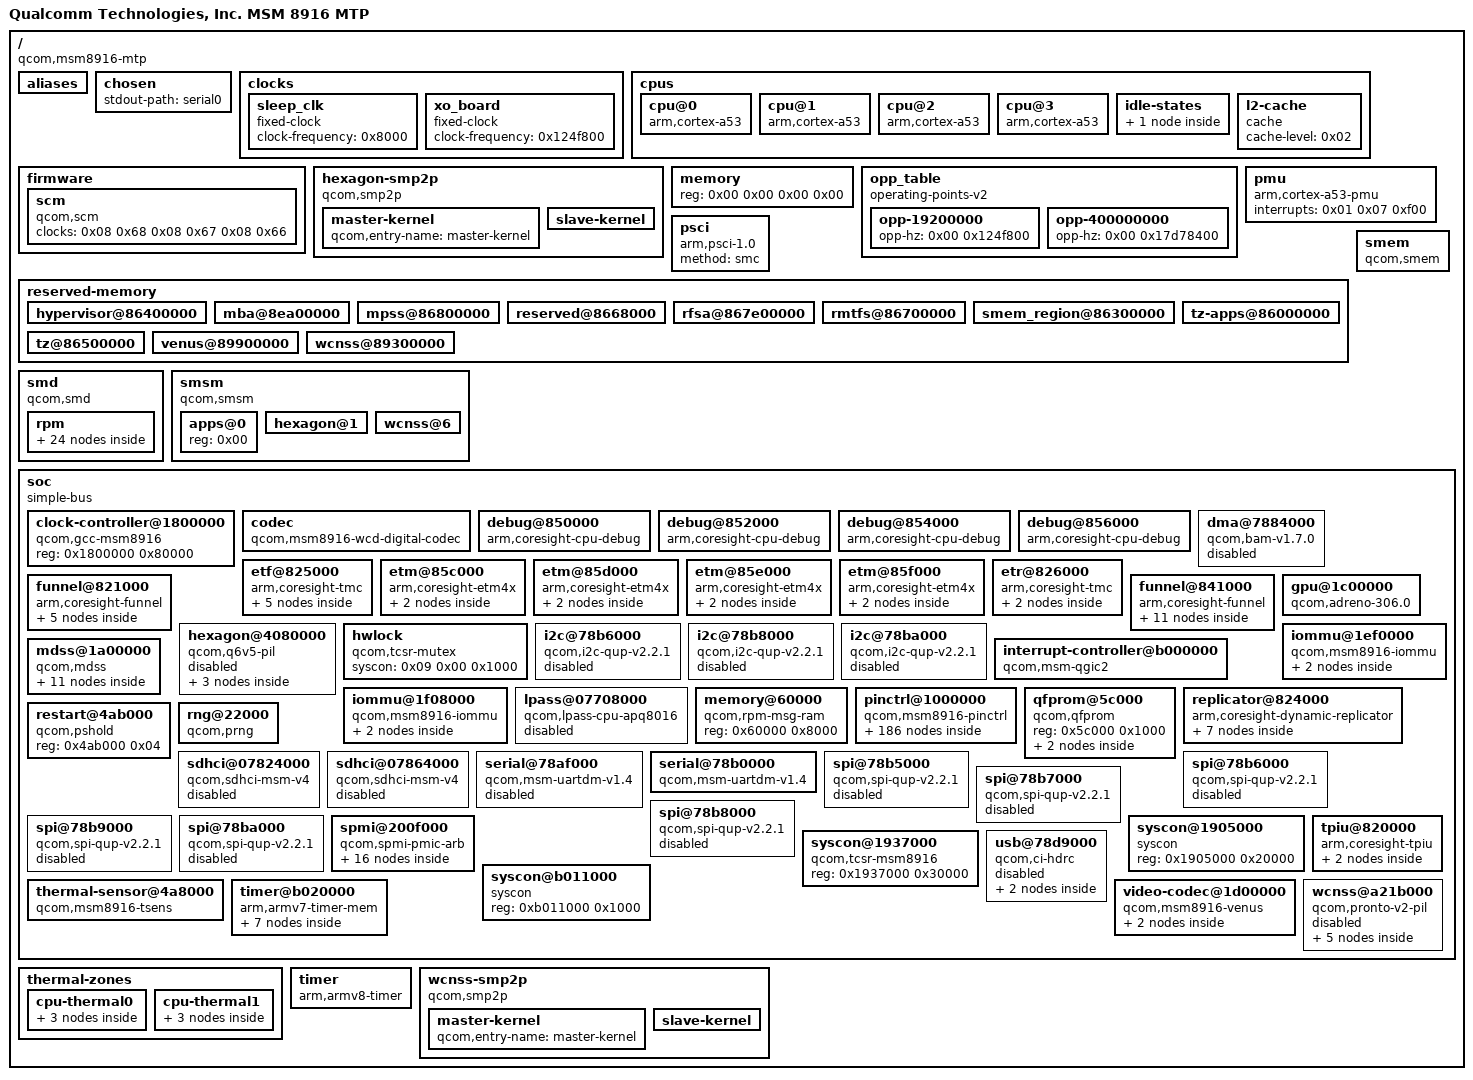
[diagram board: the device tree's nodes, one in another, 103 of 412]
/dts-v1/;

/ {
	#address-cells = <0x02>;
	#size-cells = <0x02>;
	compatible = "qcom,msm8916-mtp\0qcom,msm8916-mtp/1\0qcom,msm8916\0qcom,mtp";
	interrupt-parent = <0x01>;
	model = "Qualcomm Technologies, Inc. MSM 8916 MTP";

	__symbols__ {
		CPU0 = "/cpus/cpu@0";
		CPU1 = "/cpus/cpu@1";
		CPU2 = "/cpus/cpu@2";
		CPU3 = "/cpus/cpu@3";
		CPU_SPC = "/cpus/idle-states/spc";
		L2_0 = "/cpus/l2-cache";
		apcs = "/soc/syscon@b011000";
		apps_iommu = "/soc/iommu@1ef0000";
		apps_smsm = "/smsm/apps@0";
		blsp1_uart1 = "/soc/serial@78af000";
		blsp1_uart1_default = "/soc/pinctrl@1000000/blsp1_uart1_default";
		blsp1_uart1_sleep = "/soc/pinctrl@1000000/blsp1_uart1_sleep";
		blsp1_uart2 = "/soc/serial@78b0000";
		blsp1_uart2_default = "/soc/pinctrl@1000000/blsp1_uart2_default";
		blsp1_uart2_sleep = "/soc/pinctrl@1000000/blsp1_uart2_sleep";
		blsp_dma = "/soc/dma@7884000";
		blsp_i2c2 = "/soc/i2c@78b6000";
		blsp_i2c4 = "/soc/i2c@78b8000";
		blsp_i2c6 = "/soc/i2c@78ba000";
		blsp_spi1 = "/soc/spi@78b5000";
		blsp_spi2 = "/soc/spi@78b6000";
		blsp_spi3 = "/soc/spi@78b7000";
		blsp_spi4 = "/soc/spi@78b8000";
		blsp_spi5 = "/soc/spi@78b9000";
		blsp_spi6 = "/soc/spi@78ba000";
		cdc_dmic_lines_act = "/soc/pinctrl@1000000/cdc-dmic-lines/dmic_lines_on";
		cdc_dmic_lines_sus = "/soc/pinctrl@1000000/cdc-dmic-lines/dmic_lines_off";
		cdc_pdm_lines_act = "/soc/pinctrl@1000000/cdc-pdm-lines/pdm_lines_on";
		cdc_pdm_lines_sus = "/soc/pinctrl@1000000/cdc-pdm-lines/pdm_lines_off";
		cpu_alert0 = "/thermal-zones/cpu-thermal0/trips/trip0";
		cpu_alert1 = "/thermal-zones/cpu-thermal1/trips/trip0";
		cpu_crit0 = "/thermal-zones/cpu-thermal0/trips/trip1";
		cpu_crit1 = "/thermal-zones/cpu-thermal1/trips/trip1";
		cross_conn_det_act = "/soc/pinctrl@1000000/cross-conn-det/lines_on";
		cross_conn_det_sus = "/soc/pinctrl@1000000/cross-conn-det/lines_off";
		dsi0 = "/soc/mdss@1a00000/dsi@1a98000";
		dsi0_in = "/soc/mdss@1a00000/dsi@1a98000/ports/port@0/endpoint";
		dsi0_out = "/soc/mdss@1a00000/dsi@1a98000/ports/port@1/endpoint";
		dsi_phy0 = "/soc/mdss@1a00000/dsi-phy@1a98300";
		etf_in = "/soc/etf@825000/ports/port@0/endpoint";
		etf_out = "/soc/etf@825000/ports/port@1/endpoint";
		etm0_out = "/soc/etm@85c000/port/endpoint";
		etm1_out = "/soc/etm@85d000/port/endpoint";
		etm2_out = "/soc/etm@85e000/port/endpoint";
		etm3_out = "/soc/etm@85f000/port/endpoint";
		etr_in = "/soc/etr@826000/port/endpoint";
		ext_codec_lines_act = "/soc/pinctrl@1000000/ext-codec-lines/lines_on";
		ext_codec_lines_sus = "/soc/pinctrl@1000000/ext-codec-lines/lines_off";
		ext_mclk_tlmm_lines_act = "/soc/pinctrl@1000000/ext-mclk-tlmm-lines/mclk_lines_on";
		ext_mclk_tlmm_lines_sus = "/soc/pinctrl@1000000/ext-mclk-tlmm-lines/mclk_lines_off";
		ext_pri_tlmm_lines_act = "/soc/pinctrl@1000000/ext-pri-tlmm-lines/ext_pa_on";
		ext_pri_tlmm_lines_sus = "/soc/pinctrl@1000000/ext-pri-tlmm-lines/ext_pa_off";
		ext_pri_ws_act = "/soc/pinctrl@1000000/ext-pri-ws-line/ext_pa_on";
		ext_pri_ws_sus = "/soc/pinctrl@1000000/ext-pri-ws-line/ext_pa_off";
		ext_sec_tlmm_lines_act = "/soc/pinctrl@1000000/ext-sec-tlmm-lines/tlmm_lines_on";
		ext_sec_tlmm_lines_sus = "/soc/pinctrl@1000000/ext-sec-tlmm-lines/tlmm_lines_off";
		funnel0_in4 = "/soc/funnel@821000/ports/port@4/endpoint";
		funnel0_out = "/soc/funnel@821000/ports/port@8/endpoint";
		funnel1_in0 = "/soc/funnel@841000/ports/port@0/endpoint";
		funnel1_in1 = "/soc/funnel@841000/ports/port@1/endpoint";
		funnel1_in2 = "/soc/funnel@841000/ports/port@2/endpoint";
		funnel1_in3 = "/soc/funnel@841000/ports/port@3/endpoint";
		funnel1_out = "/soc/funnel@841000/ports/port@4/endpoint";
		gcc = "/soc/clock-controller@1800000";
		gpu_iommu = "/soc/iommu@1f08000";
		gpu_opp_table = "/opp_table";
		hexagon_smp2p_in = "/hexagon-smp2p/slave-kernel";
		hexagon_smp2p_out = "/hexagon-smp2p/master-kernel";
		hexagon_smsm = "/smsm/hexagon@1";
		i2c2_default = "/soc/pinctrl@1000000/i2c2_default";
		i2c2_sleep = "/soc/pinctrl@1000000/i2c2_sleep";
		i2c4_default = "/soc/pinctrl@1000000/i2c4_default";
		i2c4_sleep = "/soc/pinctrl@1000000/i2c4_sleep";
		i2c6_default = "/soc/pinctrl@1000000/i2c6_default";
		i2c6_sleep = "/soc/pinctrl@1000000/i2c6_sleep";
		intc = "/soc/interrupt-controller@b000000";
		lpass = "/soc/lpass@07708000";
		lpass_codec = "/soc/codec";
		mba_mem = "/reserved-memory/mba@8ea00000";
		mdp = "/soc/mdss@1a00000/mdp@1a01000";
		mdp5_intf1_out = "/soc/mdss@1a00000/mdp@1a01000/ports/port@0/endpoint";
		mdss = "/soc/mdss@1a00000";
		mpss_mem = "/reserved-memory/mpss@86800000";
		msmgpio = "/soc/pinctrl@1000000";
		otg = "/soc/usb@78d9000";
		pm8916_0 = "/soc/spmi@200f000/pm8916@0";
		pm8916_1 = "/soc/spmi@200f000/pm8916@1";
		pm8916_gpios = "/soc/spmi@200f000/pm8916@0/gpios@c000";
		pm8916_l1 = "/smd/rpm/rpm_requests/pm8916-regulators/l1";
		pm8916_l10 = "/smd/rpm/rpm_requests/pm8916-regulators/l10";
		pm8916_l11 = "/smd/rpm/rpm_requests/pm8916-regulators/l11";
		pm8916_l12 = "/smd/rpm/rpm_requests/pm8916-regulators/l12";
		pm8916_l13 = "/smd/rpm/rpm_requests/pm8916-regulators/l13";
		pm8916_l14 = "/smd/rpm/rpm_requests/pm8916-regulators/l14";
		pm8916_l15 = "/smd/rpm/rpm_requests/pm8916-regulators/l15";
		pm8916_l16 = "/smd/rpm/rpm_requests/pm8916-regulators/l16";
		pm8916_l17 = "/smd/rpm/rpm_requests/pm8916-regulators/l17";
		pm8916_l18 = "/smd/rpm/rpm_requests/pm8916-regulators/l18";
		pm8916_l2 = "/smd/rpm/rpm_requests/pm8916-regulators/l2";
		pm8916_l3 = "/smd/rpm/rpm_requests/pm8916-regulators/l3";
		pm8916_l4 = "/smd/rpm/rpm_requests/pm8916-regulators/l4";
		pm8916_l5 = "/smd/rpm/rpm_requests/pm8916-regulators/l5";
		pm8916_l6 = "/smd/rpm/rpm_requests/pm8916-regulators/l6";
		pm8916_l7 = "/smd/rpm/rpm_requests/pm8916-regulators/l7";
		pm8916_l8 = "/smd/rpm/rpm_requests/pm8916-regulators/l8";
		pm8916_l9 = "/smd/rpm/rpm_requests/pm8916-regulators/l9";
		pm8916_mpps = "/soc/spmi@200f000/pm8916@0/mpps@a000";
		pm8916_s1 = "/smd/rpm/rpm_requests/pm8916-regulators/s1";
		pm8916_s3 = "/smd/rpm/rpm_requests/pm8916-regulators/s3";
		pm8916_s4 = "/smd/rpm/rpm_requests/pm8916-regulators/s4";
		pm8916_temp = "/soc/spmi@200f000/pm8916@0/temp-alarm@2400";
		pm8916_vadc = "/soc/spmi@200f000/pm8916@0/vadc@3100";
		pronto = "/soc/wcnss@a21b000";
		qfprom = "/soc/qfprom@5c000";
		replicator_in = "/soc/replicator@824000/ports/port@2/endpoint";
		replicator_out0 = "/soc/replicator@824000/ports/port@0/endpoint";
		replicator_out1 = "/soc/replicator@824000/ports/port@1/endpoint";
		rpm_msg_ram = "/soc/memory@60000";
		rpmcc = "/smd/rpm/rpm_requests/qcom,rpmcc";
		scm = "/firmware/scm";
		sdc1_clk_off = "/soc/pinctrl@1000000/pmx_sdc1_clk/clk_off";
		sdc1_clk_on = "/soc/pinctrl@1000000/pmx_sdc1_clk/clk_on";
		sdc1_cmd_off = "/soc/pinctrl@1000000/pmx_sdc1_cmd/cmd_off";
		sdc1_cmd_on = "/soc/pinctrl@1000000/pmx_sdc1_cmd/cmd_on";
		sdc1_data_off = "/soc/pinctrl@1000000/pmx_sdc1_data/data_off";
		sdc1_data_on = "/soc/pinctrl@1000000/pmx_sdc1_data/data_on";
		sdc2_cd_off = "/soc/pinctrl@1000000/sdhc2_cd_pin/cd_off";
		sdc2_cd_on = "/soc/pinctrl@1000000/sdhc2_cd_pin/cd_on";
		sdc2_clk_off = "/soc/pinctrl@1000000/pmx_sdc2_clk/clk_off";
		sdc2_clk_on = "/soc/pinctrl@1000000/pmx_sdc2_clk/clk_on";
		sdc2_cmd_off = "/soc/pinctrl@1000000/pmx_sdc2_cmd/cmd_off";
		sdc2_cmd_on = "/soc/pinctrl@1000000/pmx_sdc2_cmd/cmd_on";
		sdc2_data_off = "/soc/pinctrl@1000000/pmx_sdc2_data/data_off";
		sdc2_data_on = "/soc/pinctrl@1000000/pmx_sdc2_data/data_on";
		sdhc_1 = "/soc/sdhci@07824000";
		sdhc_2 = "/soc/sdhci@07864000";
		sleep_clk = "/clocks/sleep_clk";
		smd_rpm_regulators = "/smd/rpm/rpm_requests/pm8916-regulators";
		smem_mem = "/reserved-memory/smem_region@86300000";
		soc = "/soc";
		spi1_default = "/soc/pinctrl@1000000/spi1_default";
		spi1_sleep = "/soc/pinctrl@1000000/spi1_sleep";
		spi2_default = "/soc/pinctrl@1000000/spi2_default";
		spi2_sleep = "/soc/pinctrl@1000000/spi2_sleep";
		spi3_default = "/soc/pinctrl@1000000/spi3_default";
		spi3_sleep = "/soc/pinctrl@1000000/spi3_sleep";
		spi4_default = "/soc/pinctrl@1000000/spi4_default";
		spi4_sleep = "/soc/pinctrl@1000000/spi4_sleep";
		spi5_default = "/soc/pinctrl@1000000/spi5_default";
		spi5_sleep = "/soc/pinctrl@1000000/spi5_sleep";
		spi6_default = "/soc/pinctrl@1000000/spi6_default";
		spi6_sleep = "/soc/pinctrl@1000000/spi6_sleep";
		spmi_bus = "/soc/spmi@200f000";
		tcsr = "/soc/syscon@1937000";
		tcsr_mutex = "/soc/hwlock";
		tcsr_mutex_regs = "/soc/syscon@1905000";
		tpiu_in = "/soc/tpiu@820000/port/endpoint";
		tsens = "/soc/thermal-sensor@4a8000";
		tsens_caldata = "/soc/qfprom@5c000/caldata@d0";
		tsens_calsel = "/soc/qfprom@5c000/calsel@ec";
		usb_hs_phy = "/soc/usb@78d9000/ulpi/phy";
		venus = "/soc/video-codec@1d00000";
		venus_mem = "/reserved-memory/venus@89900000";
		wcd_codec = "/soc/spmi@200f000/pm8916@1/codec@f000";
		wcnss_mem = "/reserved-memory/wcnss@89300000";
		wcnss_pin_a = "/soc/pinctrl@1000000/wcnss-active";
		wcnss_smp2p_in = "/wcnss-smp2p/slave-kernel";
		wcnss_smp2p_out = "/wcnss-smp2p/master-kernel";
		wcnss_smsm = "/smsm/wcnss@6";
		xo_board = "/clocks/xo_board";
	};

	aliases {
		sdhc1 = "/soc/sdhci@07824000";
		sdhc2 = "/soc/sdhci@07864000";
		serial0 = "/soc/serial@78b0000";
		usid0 = "/soc/spmi@200f000/pm8916@0";
	};

	chosen {
		stdout-path = "serial0";
	};

	clocks {

		sleep_clk {
			#clock-cells = <0x00>;
			clock-frequency = <0x8000>;
			compatible = "fixed-clock";
			phandle = <0x5d>;
		};

		xo_board {
			#clock-cells = <0x00>;
			clock-frequency = <0x124f800>;
			compatible = "fixed-clock";
			phandle = <0x1f>;
		};
	};

	cpus {
		#address-cells = <0x01>;
		#size-cells = <0x00>;

		cpu@0 {
			compatible = "arm,cortex-a53\0arm,armv8";
			cpu-idle-states = <0x03>;
			device_type = "cpu";
			enable-method = "psci";
			next-level-cache = <0x02>;
			phandle = <0x50>;
			reg = <0x00>;
		};

		cpu@1 {
			compatible = "arm,cortex-a53\0arm,armv8";
			cpu-idle-states = <0x03>;
			device_type = "cpu";
			enable-method = "psci";
			next-level-cache = <0x02>;
			phandle = <0x51>;
			reg = <0x01>;
		};

		cpu@2 {
			compatible = "arm,cortex-a53\0arm,armv8";
			cpu-idle-states = <0x03>;
			device_type = "cpu";
			enable-method = "psci";
			next-level-cache = <0x02>;
			phandle = <0x52>;
			reg = <0x02>;
		};

		cpu@3 {
			compatible = "arm,cortex-a53\0arm,armv8";
			cpu-idle-states = <0x03>;
			device_type = "cpu";
			enable-method = "psci";
			next-level-cache = <0x02>;
			phandle = <0x53>;
			reg = <0x03>;
		};

		idle-states {

			spc {
				arm,psci-suspend-param = <0x40000002>;
				compatible = "arm,idle-state";
				entry-latency-us = <0x82>;
				exit-latency-us = <0x96>;
				local-timer-stop;
				min-residency-us = <0x7d0>;
				phandle = <0x03>;
			};
		};

		l2-cache {
			cache-level = <0x02>;
			compatible = "cache";
			phandle = <0x02>;
		};
	};

	firmware {

		scm {
			#reset-cells = <0x01>;
			clock-names = "core\0bus\0iface";
			clocks = <0x08 0x68 0x08 0x67 0x08 0x66>;
			compatible = "qcom,scm";
			phandle = <0x31>;
		};
	};

	hexagon-smp2p {
		compatible = "qcom,smp2p";
		interrupts = <0x00 0x1b 0x01>;
		qcom,ipc = <0x38 0x08 0x0e>;
		qcom,local-pid = <0x00>;
		qcom,remote-pid = <0x01>;
		qcom,smem = <0x1b3 0x1ac>;

		master-kernel {
			#qcom,smem-state-cells = <0x01>;
			phandle = <0x30>;
			qcom,entry-name = "master-kernel";
		};

		slave-kernel {
			#interrupt-cells = <0x02>;
			interrupt-controller;
			phandle = <0x2f>;
			qcom,entry-name = "slave-kernel";
		};
	};

	memory {
		device_type = "memory";
		reg = <0x00 0x00 0x00 0x00>;
	};

	opp_table {
		compatible = "operating-points-v2";
		phandle = <0x28>;

		opp-19200000 {
			opp-hz = <0x00 0x124f800>;
		};

		opp-400000000 {
			opp-hz = <0x00 0x17d78400>;
		};
	};

	pmu {
		compatible = "arm,cortex-a53-pmu";
		interrupts = <0x01 0x07 0xf00>;
	};

	psci {
		compatible = "arm,psci-1.0";
		method = "smc";
	};

	reserved-memory {
		#address-cells = <0x02>;
		#size-cells = <0x02>;
		ranges;

		hypervisor@86400000 {
			no-map;
			reg = <0x00 0x86400000 0x00 0x100000>;
		};

		mba@8ea00000 {
			no-map;
			phandle = <0x36>;
			reg = <0x00 0x8ea00000 0x00 0x100000>;
		};

		mpss@86800000 {
			no-map;
			phandle = <0x37>;
			reg = <0x00 0x86800000 0x00 0x2b00000>;
		};

		reserved@8668000 {
			no-map;
			reg = <0x00 0x86680000 0x00 0x80000>;
		};

		rfsa@867e00000 {
			no-map;
			reg = <0x00 0x867e0000 0x00 0x20000>;
		};

		rmtfs@86700000 {
			no-map;
			reg = <0x00 0x86700000 0x00 0xe0000>;
		};

		smem_region@86300000 {
			no-map;
			phandle = <0x05>;
			reg = <0x00 0x86300000 0x00 0x100000>;
		};

		tz-apps@86000000 {
			no-map;
			reg = <0x00 0x86000000 0x00 0x300000>;
		};

		tz@86500000 {
			no-map;
			reg = <0x00 0x86500000 0x00 0x180000>;
		};

		venus@89900000 {
			no-map;
			phandle = <0x58>;
			reg = <0x00 0x89900000 0x00 0x600000>;
		};

		wcnss@89300000 {
			no-map;
			phandle = <0x39>;
			reg = <0x00 0x89300000 0x00 0x600000>;
		};
	};

	smd {
		compatible = "qcom,smd";

		rpm {
			interrupts = <0x00 0xa8 0x01>;
			qcom,ipc = <0x38 0x08 0x00>;
			qcom,smd-edge = <0x0f>;

			rpm_requests {
				compatible = "qcom,rpm-msm8916";
				qcom,smd-channels = "rpm_requests";

				pm8916-regulators {
					compatible = "qcom,rpm-pm8916-regulators";
					phandle = <0x9a>;

					l1 {
						phandle = <0x9c>;
					};

					l10 {
						phandle = <0xa1>;
					};

					l11 {
						phandle = <0xa2>;
					};

					l12 {
						phandle = <0xa3>;
					};

					l13 {
						phandle = <0x25>;
					};

					l14 {
						phandle = <0xa4>;
					};

					l15 {
						phandle = <0xa5>;
					};

					l16 {
						phandle = <0xa6>;
					};

					l17 {
						phandle = <0xa7>;
					};

					l18 {
						phandle = <0xa8>;
					};

					l2 {
						phandle = <0x9d>;
					};

					l3 {
						phandle = <0x33>;
					};

					l4 {
						phandle = <0x9e>;
					};

					l5 {
						phandle = <0x24>;
					};

					l6 {
						phandle = <0x9f>;
					};

					l7 {
						phandle = <0x34>;
					};

					l8 {
						phandle = <0xa0>;
					};

					l9 {
						phandle = <0x3f>;
					};

					s1 {
						phandle = <0x32>;
					};

					s3 {
						phandle = <0x3e>;
					};

					s4 {
						phandle = <0x9b>;
					};
				};

				qcom,rpmcc {
					#clock-cells = <0x01>;
					compatible = "qcom,rpmcc-msm8916";
					phandle = <0x3d>;
				};
			};
		};
	};

	smem {
		compatible = "qcom,smem";
		hwlocks = <0x07 0x03>;
		memory-region = <0x05>;
		qcom,rpm-msg-ram = <0x06>;
	};

	smsm {
		#address-cells = <0x01>;
		#size-cells = <0x00>;
		compatible = "qcom,smsm";
		qcom,ipc-1 = <0x38 0x08 0x0d>;
		qcom,ipc-3 = <0x38 0x08 0x13>;

		apps@0 {
			#qcom,smem-state-cells = <0x01>;
			phandle = <0x41>;
			reg = <0x00>;
		};

		hexagon@1 {
			#interrupt-cells = <0x02>;
			interrupt-controller;
			interrupts = <0x00 0x1a 0x01>;
			phandle = <0xa9>;
			reg = <0x01>;
		};

		wcnss@6 {
			#interrupt-cells = <0x02>;
			interrupt-controller;
			interrupts = <0x00 0x90 0x01>;
			phandle = <0xaa>;
			reg = <0x06>;
		};
	};

	soc {
		#address-cells = <0x01>;
		#size-cells = <0x01>;
		compatible = "simple-bus";
		phandle = <0x5e>;
		ranges = <0x00 0x00 0x00 0xffffffff>;

		clock-controller@1800000 {
			#clock-cells = <0x01>;
			#power-domain-cells = <0x01>;
			#reset-cells = <0x01>;
			compatible = "qcom,gcc-msm8916";
			phandle = <0x08>;
			reg = <0x1800000 0x80000>;
		};

		codec {
			#sound-dai-cells = <0x01>;
			clock-names = "ahbix-clk\0mclk";
			clocks = <0x08 0x9a 0x08 0x9f>;
			compatible = "qcom,msm8916-wcd-digital-codec";
			phandle = <0x8c>;
			reg = <0x771c000 0x400>;
		};

		debug@850000 {
			clock-names = "apb_pclk";
			clocks = <0x3d 0x08>;
			compatible = "arm,coresight-cpu-debug\0arm,primecell";
			cpu = <0x50>;
			reg = <0x850000 0x1000>;
		};

		debug@852000 {
			clock-names = "apb_pclk";
			clocks = <0x3d 0x08>;
			compatible = "arm,coresight-cpu-debug\0arm,primecell";
			cpu = <0x51>;
			reg = <0x852000 0x1000>;
		};

		debug@854000 {
			clock-names = "apb_pclk";
			clocks = <0x3d 0x08>;
			compatible = "arm,coresight-cpu-debug\0arm,primecell";
			cpu = <0x52>;
			reg = <0x854000 0x1000>;
		};

		debug@856000 {
			clock-names = "apb_pclk";
			clocks = <0x3d 0x08>;
			compatible = "arm,coresight-cpu-debug\0arm,primecell";
			cpu = <0x53>;
			reg = <0x856000 0x1000>;
		};

		dma@7884000 {
			#dma-cells = <0x01>;
			clock-names = "bam_clk";
			clocks = <0x08 0x36>;
			compatible = "qcom,bam-v1.7.0";
			interrupts = <0x00 0xee 0x04>;
			phandle = <0x0a>;
			qcom,ee = <0x00>;
			reg = <0x7884000 0x23000>;
			status = "disabled";
		};

		etf@825000 {
			clock-names = "apb_pclk\0atclk";
			clocks = <0x3d 0x08 0x3d 0x09>;
			compatible = "arm,coresight-tmc\0arm,primecell";
			reg = <0x825000 0x1000>;

			ports {
				#address-cells = <0x01>;
				#size-cells = <0x00>;

				port@0 {
					reg = <0x00>;

					endpoint {
						phandle = <0x44>;
						remote-endpoint = <0x48>;
						slave-mode;
					};
				};

				port@1 {
					reg = <0x00>;

					endpoint {
						phandle = <0x47>;
						remote-endpoint = <0x49>;
					};
				};
			};
		};

		etm@85c000 {
			clock-names = "apb_pclk\0atclk";
			clocks = <0x3d 0x08 0x3d 0x09>;
			compatible = "arm,coresight-etm4x\0arm,primecell";
			cpu = <0x50>;
			reg = <0x85c000 0x1000>;

			port {

				endpoint {
					phandle = <0x4b>;
					remote-endpoint = <0x54>;
				};
			};
		};

		etm@85d000 {
			clock-names = "apb_pclk\0atclk";
			clocks = <0x3d 0x08 0x3d 0x09>;
			compatible = "arm,coresight-etm4x\0arm,primecell";
			cpu = <0x51>;
			reg = <0x85d000 0x1000>;

			port {

				endpoint {
					phandle = <0x4c>;
					remote-endpoint = <0x55>;
				};
			};
		};

		etm@85e000 {
			clock-names = "apb_pclk\0atclk";
			clocks = <0x3d 0x08 0x3d 0x09>;
			compatible = "arm,coresight-etm4x\0arm,primecell";
			cpu = <0x52>;
			reg = <0x85e000 0x1000>;

			port {

				endpoint {
					phandle = <0x4d>;
					remote-endpoint = <0x56>;
				};
			};
		};

		etm@85f000 {
			clock-names = "apb_pclk\0atclk";
			clocks = <0x3d 0x08 0x3d 0x09>;
			compatible = "arm,coresight-etm4x\0arm,primecell";
			cpu = <0x53>;
			reg = <0x85f000 0x1000>;

			port {

				endpoint {
					phandle = <0x4e>;
					remote-endpoint = <0x57>;
				};
			};
		};

		etr@826000 {
			clock-names = "apb_pclk\0atclk";
			clocks = <0x3d 0x08 0x3d 0x09>;
			compatible = "arm,coresight-tmc\0arm,primecell";
			reg = <0x826000 0x1000>;

			port {

				endpoint {
					phandle = <0x45>;
					remote-endpoint = <0x4a>;
					slave-mode;
				};
			};
		};

		funnel@821000 {
			clock-names = "apb_pclk\0atclk";
			clocks = <0x3d 0x08 0x3d 0x09>;
			compatible = "arm,coresight-funnel\0arm,primecell";
			reg = <0x821000 0x1000>;

			ports {
				#address-cells = <0x01>;
				#size-cells = <0x00>;

				port@4 {
					reg = <0x04>;

					endpoint {
						phandle = <0x4f>;
						remote-endpoint = <0x43>;
						slave-mode;
					};
				};

				port@8 {
					reg = <0x00>;

					endpoint {
						phandle = <0x48>;
						remote-endpoint = <0x44>;
					};
				};
			};
		};

		funnel@841000 {
			clock-names = "apb_pclk\0atclk";
			clocks = <0x3d 0x08 0x3d 0x09>;
			compatible = "arm,coresight-funnel\0arm,primecell";
			reg = <0x841000 0x1000>;

			ports {
				#address-cells = <0x01>;
				#size-cells = <0x00>;

				port@0 {
					reg = <0x00>;

					endpoint {
						phandle = <0x54>;
						remote-endpoint = <0x4b>;
						slave-mode;
					};
				};

				port@1 {
					reg = <0x01>;

					endpoint {
						phandle = <0x55>;
						remote-endpoint = <0x4c>;
						slave-mode;
					};
				};

				port@2 {
					reg = <0x02>;

					endpoint {
						phandle = <0x56>;
						remote-endpoint = <0x4d>;
						slave-mode;
					};
				};

				port@3 {
					reg = <0x03>;

					endpoint {
						phandle = <0x57>;
						remote-endpoint = <0x4e>;
						slave-mode;
					};
				};

				port@4 {
					reg = <0x00>;

					endpoint {
						phandle = <0x43>;
						remote-endpoint = <0x4f>;
					};
				};
			};
		};

		gpu@1c00000 {
			clock-names = "core\0iface\0mem\0mem_iface\0alt_mem_iface\0gfx3d";
			clocks = <0x08 0x76 0x08 0x75 0x08 0x69 0x08 0x8e 0x08 0x8f 0x08 0x0e>;
			compatible = "qcom,adreno-306.0\0qcom,adreno";
			interrupt-names = "kgsl_3d0_irq";
			interrupts = <0x00 0x21 0x04>;
			iommus = <0x29 0x01 0x29 0x02>;
			operating-points-v2 = <0x28>;
			power-domains = <0x08 0x05>;
			reg = <0x1c00000 0x20000>;
			reg-names = "kgsl_3d0_reg_memory";
		};

		hexagon@4080000 {
			clock-names = "iface\0bus\0mem\0xo";
			clocks = <0x08 0x74 0x08 0xa0 0x08 0x46 0x1f>;
			compatible = "qcom,q6v5-pil";
			cx-supply = <0x32>;
			interrupt-names = "wdog\0fatal\0ready\0handover\0stop-ack";
			interrupts-extended = <0x01 0x00 0x18 0x01 0x2f 0x00 0x00 0x2f 0x01 0x00 0x2f 0x02 0x00 0x2f 0x03 0x00>;
			mx-supply = <0x33>;
			pll-supply = <0x34>;
			qcom,halt-regs = <0x35 0x18000 0x19000 0x1a000>;
			qcom,smem-state-names = "stop";
			qcom,smem-states = <0x30 0x00>;
			reg = <0x4080000 0x100 0x4020000 0x40>;
			reg-names = "qdsp6\0rmb";
			reset-names = "mss_restart";
			resets = <0x31 0x00>;
			status = "disabled";

			mba {
				memory-region = <0x36>;
			};

			mpss {
				memory-region = <0x37>;
			};

			smd-edge {
				interrupts = <0x00 0x19 0x01>;
				label = "hexagon";
				qcom,ipc = <0x38 0x08 0x0c>;
				qcom,remote-pid = <0x01>;
				qcom,smd-edge = <0x00>;
			};
		};

		hwlock {
			#hwlock-cells = <0x01>;
			compatible = "qcom,tcsr-mutex";
			phandle = <0x07>;
			syscon = <0x09 0x00 0x1000>;
		};

		i2c@78b6000 {
			#address-cells = <0x01>;
			#size-cells = <0x00>;
			clock-names = "iface\0core";
			clocks = <0x08 0x36 0x08 0x3a>;
			compatible = "qcom,i2c-qup-v2.2.1";
			interrupts = <0x00 0x60 0x00>;
			phandle = <0x88>;
			pinctrl-0 = <0x19>;
			pinctrl-1 = <0x1a>;
			pinctrl-names = "default\0sleep";
			reg = <0x78b6000 0x1000>;
			status = "disabled";
		};

		i2c@78b8000 {
			#address-cells = <0x01>;
			#size-cells = <0x00>;
			clock-names = "iface\0core";
			clocks = <0x08 0x36 0x08 0x3e>;
			compatible = "qcom,i2c-qup-v2.2.1";
			interrupts = <0x00 0x62 0x00>;
			phandle = <0x89>;
			pinctrl-0 = <0x1b>;
			pinctrl-1 = <0x1c>;
			pinctrl-names = "default\0sleep";
			reg = <0x78b8000 0x1000>;
			status = "disabled";
		};

		i2c@78ba000 {
			#address-cells = <0x01>;
			#size-cells = <0x00>;
			clock-names = "iface\0core";
			clocks = <0x08 0x36 0x08 0x42>;
			compatible = "qcom,i2c-qup-v2.2.1";
			interrupts = <0x00 0x64 0x00>;
			phandle = <0x8a>;
			pinctrl-0 = <0x1d>;
			pinctrl-1 = <0x1e>;
			pinctrl-names = "default\0sleep";
			reg = <0x78ba000 0x1000>;
			status = "disabled";
		};

		interrupt-controller@b000000 {
			#interrupt-cells = <0x03>;
			compatible = "qcom,msm-qgic2";
			interrupt-controller;
			phandle = <0x01>;
			reg = <0xb000000 0x1000 0xb002000 0x1000>;
		};

		iommu@1ef0000 {
			#address-cells = <0x01>;
			#iommu-cells = <0x01>;
			#size-cells = <0x01>;
			clock-names = "iface\0bus";
			clocks = <0x08 0x81 0x08 0x8b>;
			compatible = "qcom,msm8916-iommu\0qcom,msm-iommu-v1";
			phandle = <0x2b>;
			qcom,iommu-secure-id = <0x11>;
			ranges = <0x00 0x1e20000 0x40000>;
			reg = <0x1ef0000 0x3000>;

			iommu-ctx@4000 {
				compatible = "qcom,msm-iommu-v1-ns";
				interrupts = <0x00 0x46 0x04>;
				reg = <0x4000 0x1000>;
			};

			iommu-ctx@5000 {
				compatible = "qcom,msm-iommu-v1-sec";
				interrupts = <0x00 0x46 0x04>;
				reg = <0x5000 0x1000>;
			};
		};

		iommu@1f08000 {
			#address-cells = <0x01>;
			#iommu-cells = <0x01>;
			#size-cells = <0x01>;
			clock-names = "iface\0bus";
			clocks = <0x08 0x81 0x08 0x8c>;
			compatible = "qcom,msm8916-iommu\0qcom,msm-iommu-v1";
			phandle = <0x29>;
			qcom,iommu-secure-id = <0x12>;
			ranges = <0x00 0x1f08000 0x10000>;

			iommu-ctx@1000 {
				compatible = "qcom,msm-iommu-v1-ns";
				interrupts = <0x00 0xf1 0x04>;
				reg = <0x1000 0x1000>;
			};

			iommu-ctx@2000 {
				compatible = "qcom,msm-iommu-v1-ns";
				interrupts = <0x00 0xf2 0x00>;
				reg = <0x2000 0x1000>;
			};
		};

		lpass@07708000 {
			#sound-dai-cells = <0x01>;
			clock-names = "ahbix-clk\0pcnoc-mport-clk\0pcnoc-sway-clk\0mi2s-bit-clk0\0mi2s-bit-clk1\0mi2s-bit-clk2\0mi2s-bit-clk3";
			clocks = <0x08 0x9a 0x08 0x96 0x08 0x97 0x08 0x9c 0x08 0x9d 0x08 0x9d 0x08 0x9e>;
			compatible = "qcom,lpass-cpu-apq8016";
			interrupt-names = "lpass-irq-lpaif";
			interrupts = <0x00 0xa0 0x00>;
			phandle = <0x8b>;
			reg = <0x7708000 0x10000>;
			reg-names = "lpass-lpaif";
			status = "disabled";
		};

		mdss@1a00000 {
			#address-cells = <0x01>;
			#interrupt-cells = <0x01>;
			#size-cells = <0x01>;
			clock-names = "iface_clk\0bus_clk\0vsync_clk";
			clocks = <0x08 0x6d 0x08 0x6e 0x08 0x73>;
			compatible = "qcom,mdss";
			interrupt-controller;
			interrupts = <0x00 0x48 0x00>;
			phandle = <0x2a>;
			power-domains = <0x08 0x02>;
			ranges;
			reg = <0x1a00000 0x1000 0x1ac8000 0x3000>;
			reg-names = "mdss_phys\0vbif_phys";

			dsi-phy@1a98300 {
				#clock-cells = <0x01>;
				#phy-cells = <0x00>;
				clock-names = "iface_clk";
				clocks = <0x08 0x6d>;
				compatible = "qcom,dsi-phy-28nm-lp";
				phandle = <0x2d>;
				reg = <0x1a98300 0xd4 0x1a98500 0x280 0x1a98780 0x30>;
				reg-names = "dsi_pll\0dsi_phy\0dsi_phy_regulator";
			};

			dsi@1a98000 {
				assigned-clock-parents = <0x2d 0x00 0x2d 0x01>;
				assigned-clocks = <0x08 0x2b 0x08 0x2e>;
				clock-names = "mdp_core_clk\0iface_clk\0bus_clk\0byte_clk\0pixel_clk\0core_clk";
				clocks = <0x08 0x71 0x08 0x6d 0x08 0x6e 0x08 0x6f 0x08 0x72 0x08 0x70>;
				compatible = "qcom,mdss-dsi-ctrl";
				interrupt-parent = <0x2a>;
				interrupts = <0x04 0x00>;
				phandle = <0x97>;
				phy-names = "dsi-phy";
				phys = <0x2d>;
				reg = <0x1a98000 0x25c>;
				reg-names = "dsi_ctrl";

				ports {
					#address-cells = <0x01>;
					#size-cells = <0x00>;

					port@0 {
						reg = <0x00>;

						endpoint {
							phandle = <0x2c>;
							remote-endpoint = <0x2e>;
						};
					};

					port@1 {
						reg = <0x01>;

						endpoint {
							phandle = <0x98>;
						};
					};
				};
			};

			mdp@1a01000 {
				clock-names = "iface_clk\0bus_clk\0core_clk\0vsync_clk";
				clocks = <0x08 0x6d 0x08 0x6e 0x08 0x71 0x08 0x73>;
				compatible = "qcom,mdp5";
				interrupt-parent = <0x2a>;
				interrupts = <0x00 0x00>;
				iommus = <0x2b 0x04>;
				phandle = <0x96>;
				reg = <0x1a01000 0x90000>;
				reg-names = "mdp_phys";

				ports {
					#address-cells = <0x01>;
					#size-cells = <0x00>;

					port@0 {
						reg = <0x00>;

						endpoint {
							phandle = <0x2e>;
							remote-endpoint = <0x2c>;
						};
					};
				};
			};
		};

		memory@60000 {
			compatible = "qcom,rpm-msg-ram";
			phandle = <0x06>;
			reg = <0x60000 0x8000>;
		};

		pinctrl@1000000 {
			#gpio-cells = <0x02>;
			#interrupt-cells = <0x02>;
			compatible = "qcom,msm8916-pinctrl";
			gpio-controller;
			interrupt-controller;
			interrupts = <0x00 0xd0 0x04>;
			phandle = <0x5f>;
			reg = <0x1000000 0x300000>;

			blsp1_uart1_default {
				phandle = <0x60>;

				pinconf {
					bias-disable;
					drive-strength = <0x10>;
					pins = "gpio0\0gpio1\0gpio2\0gpio3";
				};

				pinmux {
					function = "blsp_uart1";
					pins = "gpio0\0gpio1\0gpio2\0gpio3";
				};
			};

			blsp1_uart1_sleep {
				phandle = <0x61>;

				pinconf {
					bias-pull-down;
					drive-strength = <0x02>;
					pins = "gpio0\0gpio1\0gpio2\0gpio3";
				};

				pinmux {
					function = "gpio";
					pins = "gpio0\0gpio1\0gpio2\0gpio3";
				};
			};

			blsp1_uart2_default {
				phandle = <0x0b>;

				pinconf {
					bias-disable;
					drive-strength = <0x10>;
					pins = "gpio4\0gpio5";
				};

				pinmux {
					function = "blsp_uart2";
					pins = "gpio4\0gpio5";
				};
			};

			blsp1_uart2_sleep {
				phandle = <0x0c>;

				pinconf {
					bias-pull-down;
					drive-strength = <0x02>;
					pins = "gpio4\0gpio5";
				};

				pinmux {
					function = "gpio";
					pins = "gpio4\0gpio5";
				};
			};

			cdc-dmic-lines {

				dmic_lines_off {
					phandle = <0x7d>;

					pinconf {
						bias-disable;
						drive-strength = <0x02>;
						pins = "gpio0\0gpio1";
					};
				};

				dmic_lines_on {
					phandle = <0x7c>;

					pinconf {
						drive-strength = <0x08>;
						pins = "gpio0\0gpio1";
					};

					pinmux_dmic0_clk {
						function = "dmic0_clk";
						pins = "gpio0";
					};

					pinmux_dmic0_data {
						function = "dmic0_data";
						pins = "gpio1";
					};
				};
			};

			cdc-pdm-lines {

				pdm_lines_off {
					phandle = <0x73>;

					pinconf {
						bias-disable;
						drive-strength = <0x02>;
						pins = "gpio63\0gpio64\0gpio65\0gpio66\0gpio67\0gpio68";
					};

					pinmux {
						function = "cdc_pdm0";
						pins = "gpio63\0gpio64\0gpio65\0gpio66\0gpio67\0gpio68";
					};
				};

				pdm_lines_on {
					phandle = <0x72>;

					pinconf {
						bias-pull-none;
						drive-strength = <0x08>;
						pins = "gpio63\0gpio64\0gpio65\0gpio66\0gpio67\0gpio68";
					};

					pinmux {
						function = "cdc_pdm0";
						pins = "gpio63\0gpio64\0gpio65\0gpio66\0gpio67\0gpio68";
					};
				};
			};

			cross-conn-det {

				lines_off {
					phandle = <0x7f>;

					pinconf {
						bias-disable;
						drive-strength = <0x02>;
						pins = "gpio120";
					};

					pinmux {
						function = "gpio";
						pins = "gpio120";
					};
				};

				lines_on {
					phandle = <0x7e>;

					pinconf {
						bias-pull-down;
						drive-strength = <0x08>;
						output-low;
						pins = "gpio120";
					};

					pinmux {
						function = "gpio";
						pins = "gpio120";
					};
				};
			};

			ext-codec-lines {

				lines_off {
					phandle = <0x71>;

					pinconf {
						bias-disable;
						drive-strength = <0x02>;
						pins = "gpio67";
					};

					pinmux {
						function = "gpio";
						pins = "gpio67";
					};
				};

				lines_on {
					phandle = <0x70>;

					pinconf {
						bias-disable;
						drive-strength = <0x08>;
						output-high;
						pins = "gpio67";
					};

					pinmux {
						function = "gpio";
						pins = "gpio67";
					};
				};
			};

			ext-mclk-tlmm-lines {

				mclk_lines_off {
					phandle = <0x79>;

					pinconf {
						bias-disable;
						drive-strength = <0x02>;
						pins = "gpio116";
					};

					pinmux {
						function = "pri_mi2s";
						pins = "gpio116";
					};
				};

				mclk_lines_on {
					phandle = <0x78>;

					pinconf {
						bias-pull-none;
						drive-strength = <0x08>;
						pins = "gpio116";
					};

					pinmux {
						function = "pri_mi2s";
						pins = "gpio116";
					};
				};
			};

			ext-pri-tlmm-lines {

				ext_pa_off {
					phandle = <0x75>;

					pinconf {
						bias-disable;
						drive-strength = <0x02>;
						pins = "gpio113\0gpio114\0gpio115\0gpio116";
					};

					pinmux {
						function = "pri_mi2s";
						pins = "gpio113\0gpio114\0gpio115\0gpio116";
					};
				};

				ext_pa_on {
					phandle = <0x74>;

					pinconf {
						bias-pull-none;
						drive-strength = <0x08>;
						pins = "gpio113\0gpio114\0gpio115\0gpio116";
					};

					pinmux {
						function = "pri_mi2s";
						pins = "gpio113\0gpio114\0gpio115\0gpio116";
					};
				};
			};

			ext-pri-ws-line {

				ext_pa_off {
					phandle = <0x77>;

					pinconf {
						bias-disable;
						drive-strength = <0x02>;
						pins = "gpio110";
					};

					pinmux {
						function = "pri_mi2s_ws";
						pins = "gpio110";
					};
				};

				ext_pa_on {
					phandle = <0x76>;

					pinconf {
						bias-pull-none;
						drive-strength = <0x08>;
						pins = "gpio110";
					};

					pinmux {
						function = "pri_mi2s_ws";
						pins = "gpio110";
					};
				};
			};

			ext-sec-tlmm-lines {

				tlmm_lines_off {
					phandle = <0x7b>;

					pinconf {
						bias-disable;
						drive-strength = <0x02>;
						pins = "gpio112\0gpio117\0gpio118\0gpio119";
					};

					pinmux {
						function = "sec_mi2s";
						pins = "gpio112\0gpio117\0gpio118\0gpio119";
					};
				};

				tlmm_lines_on {
					phandle = <0x7a>;

					pinconf {
						bias-pull-none;
						drive-strength = <0x08>;
						pins = "gpio112\0gpio117\0gpio118\0gpio119";
					};

					pinmux {
						function = "sec_mi2s";
						pins = "gpio112\0gpio117\0gpio118\0gpio119";
					};
				};
			};

			i2c2_default {
				phandle = <0x19>;

				pinconf {
					bias-disable = <0x00>;
					drive-strength = <0x10>;
					pins = "gpio6\0gpio7";
				};

				pinmux {
					function = "blsp_i2c2";
					pins = "gpio6\0gpio7";
				};
			};

			i2c2_sleep {
				phandle = <0x1a>;

				pinconf {
					bias-disable = <0x00>;
					drive-strength = <0x02>;
					pins = "gpio6\0gpio7";
				};

				pinmux {
					function = "gpio";
					pins = "gpio6\0gpio7";
				};
			};

			i2c4_default {
				phandle = <0x1b>;

				pinconf {
					bias-disable = <0x00>;
					drive-strength = <0x10>;
					pins = "gpio14\0gpio15";
				};

				pinmux {
					function = "blsp_i2c4";
					pins = "gpio14\0gpio15";
				};
			};

			i2c4_sleep {
				phandle = <0x1c>;

				pinconf {
					bias-disable = <0x00>;
					drive-strength = <0x02>;
					pins = "gpio14\0gpio15";
				};

				pinmux {
					function = "gpio";
					pins = "gpio14\0gpio15";
				};
			};

			i2c6_default {
				phandle = <0x1d>;

				pinconf {
					bias-disable = <0x00>;
					drive-strength = <0x10>;
					pins = "gpio22\0gpio23";
				};

				pinmux {
					function = "blsp_i2c6";
					pins = "gpio22\0gpio23";
				};
			};

			i2c6_sleep {
				phandle = <0x1e>;

				pinconf {
					bias-disable = <0x00>;
					drive-strength = <0x02>;
					pins = "gpio22\0gpio23";
				};

				pinmux {
					function = "gpio";
					pins = "gpio22\0gpio23";
				};
			};

			pmx_sdc1_clk {

				clk_off {
					phandle = <0x65>;

					pinconf {
						bias-disable;
						drive-strength = <0x02>;
						pins = "sdc1_clk";
					};

					pinmux {
						pins = "sdc1_clk";
					};
				};

				clk_on {
					phandle = <0x64>;

					pinconf {
						bias-disable;
						drive-strength = <0x10>;
						pins = "sdc1_clk";
					};

					pinmux {
						pins = "sdc1_clk";
					};
				};
			};

			pmx_sdc1_cmd {

				cmd_off {
					phandle = <0x67>;

					pinconf {
						bias-pull-up;
						drive-strength = <0x02>;
						pins = "sdc1_cmd";
					};

					pinmux {
						pins = "sdc1_cmd";
					};
				};

				cmd_on {
					phandle = <0x66>;

					pinconf {
						bias-pull-up;
						drive-strength = <0x0a>;
						pins = "sdc1_cmd";
					};

					pinmux {
						pins = "sdc1_cmd";
					};
				};
			};

			pmx_sdc1_data {

				data_off {
					phandle = <0x69>;

					pinconf {
						bias-pull-up;
						drive-strength = <0x02>;
						pins = "sdc1_data";
					};

					pinmux {
						pins = "sdc1_data";
					};
				};

				data_on {
					phandle = <0x68>;

					pinconf {
						bias-pull-up;
						drive-strength = <0x0a>;
						pins = "sdc1_data";
					};

					pinmux {
						pins = "sdc1_data";
					};
				};
			};

			pmx_sdc2_clk {

				clk_off {
					phandle = <0x6b>;

					pinconf {
						bias-disable;
						drive-strength = <0x02>;
						pins = "sdc2_clk";
					};

					pinmux {
						pins = "sdc2_clk";
					};
				};

				clk_on {
					phandle = <0x6a>;

					pinconf {
						bias-disable;
						drive-strength = <0x10>;
						pins = "sdc2_clk";
					};

					pinmux {
						pins = "sdc2_clk";
					};
				};
			};

			pmx_sdc2_cmd {

				cmd_off {
					phandle = <0x6d>;

					pinconf {
						bias-pull-up;
						drive-strength = <0x02>;
						pins = "sdc2_cmd";
					};

					pinmux {
						pins = "sdc2_cmd";
					};
				};

				cmd_on {
					phandle = <0x6c>;

					pinconf {
						bias-pull-up;
						drive-strength = <0x0a>;
						pins = "sdc2_cmd";
					};

					pinmux {
						pins = "sdc2_cmd";
					};
				};
			};

			pmx_sdc2_data {

				data_off {
					phandle = <0x6f>;

					pinconf {
						bias-pull-up;
						drive-strength = <0x02>;
						pins = "sdc2_data";
					};

					pinmux {
						pins = "sdc2_data";
					};
				};

				data_on {
					phandle = <0x6e>;

					pinconf {
						bias-pull-up;
						drive-strength = <0x0a>;
						pins = "sdc2_data";
					};

					pinmux {
						pins = "sdc2_data";
					};
				};
			};

			sdhc2_cd_pin {

				cd_off {
					phandle = <0x63>;

					pinconf {
						bias-disable;
						drive-strength = <0x02>;
						pins = "gpio38";
					};

					pinmux {
						function = "gpio";
						pins = "gpio38";
					};
				};

				cd_on {
					phandle = <0x62>;

					pinconf {
						bias-pull-up;
						drive-strength = <0x02>;
						pins = "gpio38";
					};

					pinmux {
						function = "gpio";
						pins = "gpio38";
					};
				};
			};

			spi1_default {
				phandle = <0x0d>;

				pinconf {
					bias-disable;
					drive-strength = <0x0c>;
					pins = "gpio0\0gpio1\0gpio3";
				};

				pinconf_cs {
					bias-disable;
					drive-strength = <0x10>;
					output-high;
					pins = "gpio2";
				};

				pinmux {
					function = "blsp_spi1";
					pins = "gpio0\0gpio1\0gpio3";
				};

				pinmux_cs {
					function = "gpio";
					pins = "gpio2";
				};
			};

			spi1_sleep {
				phandle = <0x0e>;

				pinconf {
					bias-pull-down;
					drive-strength = <0x02>;
					pins = "gpio0\0gpio1\0gpio2\0gpio3";
				};

				pinmux {
					function = "gpio";
					pins = "gpio0\0gpio1\0gpio2\0gpio3";
				};
			};

			spi2_default {
				phandle = <0x0f>;

				pinconf {
					bias-disable;
					drive-strength = <0x0c>;
					pins = "gpio4\0gpio5\0gpio7";
				};

				pinconf_cs {
					bias-disable;
					drive-strength = <0x10>;
					output-high;
					pins = "gpio6";
				};

				pinmux {
					function = "blsp_spi2";
					pins = "gpio4\0gpio5\0gpio7";
				};

				pinmux_cs {
					function = "gpio";
					pins = "gpio6";
				};
			};

			spi2_sleep {
				phandle = <0x10>;

				pinconf {
					bias-pull-down;
					drive-strength = <0x02>;
					pins = "gpio4\0gpio5\0gpio6\0gpio7";
				};

				pinmux {
					function = "gpio";
					pins = "gpio4\0gpio5\0gpio6\0gpio7";
				};
			};

			spi3_default {
				phandle = <0x11>;

				pinconf {
					bias-disable;
					drive-strength = <0x0c>;
					pins = "gpio8\0gpio9\0gpio11";
				};

				pinconf_cs {
					bias-disable;
					drive-strength = <0x10>;
					output-high;
					pins = "gpio10";
				};

				pinmux {
					function = "blsp_spi3";
					pins = "gpio8\0gpio9\0gpio11";
				};

				pinmux_cs {
					function = "gpio";
					pins = "gpio10";
				};
			};

			spi3_sleep {
				phandle = <0x12>;

				pinconf {
					bias-pull-down;
					drive-strength = <0x02>;
					pins = "gpio8\0gpio9\0gpio10\0gpio11";
				};

				pinmux {
					function = "gpio";
					pins = "gpio8\0gpio9\0gpio10\0gpio11";
				};
			};

			spi4_default {
				phandle = <0x13>;

				pinconf {
					bias-disable;
					drive-strength = <0x0c>;
					pins = "gpio12\0gpio13\0gpio15";
				};

				pinconf_cs {
					bias-disable;
					drive-strength = <0x10>;
					output-high;
					pins = "gpio14";
				};

				pinmux {
					function = "blsp_spi4";
					pins = "gpio12\0gpio13\0gpio15";
				};

				pinmux_cs {
					function = "gpio";
					pins = "gpio14";
				};
			};

			spi4_sleep {
				phandle = <0x14>;

				pinconf {
					bias-pull-down;
					drive-strength = <0x02>;
					pins = "gpio12\0gpio13\0gpio14\0gpio15";
				};

				pinmux {
					function = "gpio";
					pins = "gpio12\0gpio13\0gpio14\0gpio15";
				};
			};

			spi5_default {
				phandle = <0x15>;

				pinconf {
					bias-disable;
					drive-strength = <0x0c>;
					pins = "gpio16\0gpio17\0gpio19";
				};

				pinconf_cs {
					bias-disable;
					drive-strength = <0x10>;
					output-high;
					pins = "gpio18";
				};

				pinmux {
					function = "blsp_spi5";
					pins = "gpio16\0gpio17\0gpio19";
				};

				pinmux_cs {
					function = "gpio";
					pins = "gpio18";
				};
			};

			spi5_sleep {
				phandle = <0x16>;

				pinconf {
					bias-pull-down;
					drive-strength = <0x02>;
					pins = "gpio16\0gpio17\0gpio18\0gpio19";
				};

				pinmux {
					function = "gpio";
					pins = "gpio16\0gpio17\0gpio18\0gpio19";
				};
			};

			spi6_default {
				phandle = <0x17>;

				pinconf {
					bias-disable;
					drive-strength = <0x0c>;
					pins = "gpio20\0gpio21\0gpio23";
				};

				pinconf_cs {
					bias-disable;
					drive-strength = <0x10>;
					output-high;
					pins = "gpio22";
				};

				pinmux {
					function = "blsp_spi6";
					pins = "gpio20\0gpio21\0gpio23";
				};

				pinmux_cs {
					function = "gpio";
					pins = "gpio22";
				};
			};

			spi6_sleep {
				phandle = <0x18>;

				pinconf {
					bias-pull-down;
					drive-strength = <0x02>;
					pins = "gpio20\0gpio21\0gpio22\0gpio23";
				};

				pinmux {
					function = "gpio";
					pins = "gpio20\0gpio21\0gpio22\0gpio23";
				};
			};

			wcnss-active {
				phandle = <0x3c>;

				pinconf {
					bias-pull-up;
					drive-strength = <0x06>;
					pins = "gpio40\0gpio41\0gpio42\0gpio43\0gpio44";
				};

				pinmux {
					function = "wcss_wlan";
					pins = "gpio40\0gpio41\0gpio42\0gpio43\0gpio44";
				};
			};
		};

		qfprom@5c000 {
			#address-cells = <0x01>;
			#size-cells = <0x01>;
			compatible = "qcom,qfprom";
			phandle = <0x95>;
			reg = <0x5c000 0x1000>;

			caldata@d0 {
				phandle = <0x26>;
				reg = <0xd0 0x08>;
			};

			calsel@ec {
				phandle = <0x27>;
				reg = <0xec 0x04>;
			};
		};

		replicator@824000 {
			clock-names = "apb_pclk\0atclk";
			clocks = <0x3d 0x08 0x3d 0x09>;
			compatible = "arm,coresight-dynamic-replicator\0arm,primecell";
			reg = <0x824000 0x1000>;

			ports {
				#address-cells = <0x01>;
				#size-cells = <0x00>;

				port@0 {
					reg = <0x00>;

					endpoint {
						phandle = <0x4a>;
						remote-endpoint = <0x45>;
					};
				};

				port@1 {
					reg = <0x01>;

					endpoint {
						phandle = <0x42>;
						remote-endpoint = <0x46>;
					};
				};

				port@2 {
					reg = <0x00>;

					endpoint {
						phandle = <0x49>;
						remote-endpoint = <0x47>;
						slave-mode;
					};
				};
			};
		};

		restart@4ab000 {
			compatible = "qcom,pshold";
			reg = <0x4ab000 0x04>;
		};

		rng@22000 {
			clock-names = "core";
			clocks = <0x08 0x79>;
			compatible = "qcom,prng";
			reg = <0x22000 0x200>;
		};

		sdhci@07824000 {
			bus-width = <0x08>;
			clock-names = "core\0iface\0xo";
			clocks = <0x08 0x7b 0x08 0x7a 0x1f>;
			compatible = "qcom,sdhci-msm-v4";
			interrupt-names = "hc_irq\0pwr_irq";
			interrupts = <0x00 0x7b 0x00 0x00 0x8a 0x00>;
			mmc-ddr-1_8v;
			non-removable;
			phandle = <0x8d>;
			reg = <0x7824900 0x11c 0x7824000 0x800>;
			reg-names = "hc_mem\0core_mem";
			status = "disabled";
		};

		sdhci@07864000 {
			bus-width = <0x04>;
			clock-names = "core\0iface\0xo";
			clocks = <0x08 0x7d 0x08 0x7c 0x1f>;
			compatible = "qcom,sdhci-msm-v4";
			interrupt-names = "hc_irq\0pwr_irq";
			interrupts = <0x00 0x7d 0x00 0x00 0xdd 0x00>;
			phandle = <0x8e>;
			reg = <0x7864900 0x11c 0x7864000 0x800>;
			reg-names = "hc_mem\0core_mem";
			status = "disabled";
		};

		serial@78af000 {
			clock-names = "core\0iface";
			clocks = <0x08 0x44 0x08 0x36>;
			compatible = "qcom,msm-uartdm-v1.4\0qcom,msm-uartdm";
			dma-names = "rx\0tx";
			dmas = <0x0a 0x01 0x0a 0x00>;
			interrupts = <0x00 0x6b 0x04>;
			phandle = <0x80>;
			reg = <0x78af000 0x200>;
			status = "disabled";
		};

		serial@78b0000 {
			clock-names = "core\0iface";
			clocks = <0x08 0x45 0x08 0x36>;
			compatible = "qcom,msm-uartdm-v1.4\0qcom,msm-uartdm";
			dma-names = "rx\0tx";
			dmas = <0x0a 0x03 0x0a 0x02>;
			interrupts = <0x00 0x6c 0x04>;
			phandle = <0x81>;
			pinctrl-0 = <0x0b>;
			pinctrl-1 = <0x0c>;
			pinctrl-names = "default\0sleep";
			reg = <0x78b0000 0x200>;
			status = "okay";
		};

		spi@78b5000 {
			#address-cells = <0x01>;
			#size-cells = <0x00>;
			clock-names = "core\0iface";
			clocks = <0x08 0x39 0x08 0x36>;
			compatible = "qcom,spi-qup-v2.2.1";
			dma-names = "rx\0tx";
			dmas = <0x0a 0x05 0x0a 0x04>;
			interrupts = <0x00 0x5f 0x04>;
			phandle = <0x82>;
			pinctrl-0 = <0x0d>;
			pinctrl-1 = <0x0e>;
			pinctrl-names = "default\0sleep";
			reg = <0x78b5000 0x600>;
			status = "disabled";
		};

		spi@78b6000 {
			#address-cells = <0x01>;
			#size-cells = <0x00>;
			clock-names = "core\0iface";
			clocks = <0x08 0x3b 0x08 0x36>;
			compatible = "qcom,spi-qup-v2.2.1";
			dma-names = "rx\0tx";
			dmas = <0x0a 0x07 0x0a 0x06>;
			interrupts = <0x00 0x60 0x04>;
			phandle = <0x83>;
			pinctrl-0 = <0x0f>;
			pinctrl-1 = <0x10>;
			pinctrl-names = "default\0sleep";
			reg = <0x78b6000 0x600>;
			status = "disabled";
		};

		spi@78b7000 {
			#address-cells = <0x01>;
			#size-cells = <0x00>;
			clock-names = "core\0iface";
			clocks = <0x08 0x3d 0x08 0x36>;
			compatible = "qcom,spi-qup-v2.2.1";
			dma-names = "rx\0tx";
			dmas = <0x0a 0x09 0x0a 0x08>;
			interrupts = <0x00 0x61 0x04>;
			phandle = <0x84>;
			pinctrl-0 = <0x11>;
			pinctrl-1 = <0x12>;
			pinctrl-names = "default\0sleep";
			reg = <0x78b7000 0x600>;
			status = "disabled";
		};

		spi@78b8000 {
			#address-cells = <0x01>;
			#size-cells = <0x00>;
			clock-names = "core\0iface";
			clocks = <0x08 0x3f 0x08 0x36>;
			compatible = "qcom,spi-qup-v2.2.1";
			dma-names = "rx\0tx";
			dmas = <0x0a 0x0b 0x0a 0x0a>;
			interrupts = <0x00 0x62 0x04>;
			phandle = <0x85>;
			pinctrl-0 = <0x13>;
			pinctrl-1 = <0x14>;
			pinctrl-names = "default\0sleep";
			reg = <0x78b8000 0x600>;
			status = "disabled";
		};

		spi@78b9000 {
			#address-cells = <0x01>;
			#size-cells = <0x00>;
			clock-names = "core\0iface";
			clocks = <0x08 0x41 0x08 0x36>;
			compatible = "qcom,spi-qup-v2.2.1";
			dma-names = "rx\0tx";
			dmas = <0x0a 0x0d 0x0a 0x0c>;
			interrupts = <0x00 0x63 0x04>;
			phandle = <0x86>;
			pinctrl-0 = <0x15>;
			pinctrl-1 = <0x16>;
			pinctrl-names = "default\0sleep";
			reg = <0x78b9000 0x600>;
			status = "disabled";
		};

		spi@78ba000 {
			#address-cells = <0x01>;
			#size-cells = <0x00>;
			clock-names = "core\0iface";
			clocks = <0x08 0x43 0x08 0x36>;
			compatible = "qcom,spi-qup-v2.2.1";
			dma-names = "rx\0tx";
			dmas = <0x0a 0x0f 0x0a 0x0e>;
			interrupts = <0x00 0x64 0x04>;
			phandle = <0x87>;
			pinctrl-0 = <0x17>;
			pinctrl-1 = <0x18>;
			pinctrl-names = "default\0sleep";
			reg = <0x78ba000 0x600>;
			status = "disabled";
		};

		spmi@200f000 {
			#address-cells = <0x02>;
			#interrupt-cells = <0x04>;
			#size-cells = <0x00>;
			compatible = "qcom,spmi-pmic-arb";
			interrupt-controller;
			interrupt-names = "periph_irq";
			interrupts = <0x00 0xbe 0x04>;
			phandle = <0x23>;
			qcom,channel = <0x00>;
			qcom,ee = <0x00>;
			reg = <0x200f000 0x1000 0x2400000 0x400000 0x2c00000 0x400000 0x3800000 0x200000 0x200a000 0x2100>;
			reg-names = "core\0chnls\0obsrvr\0intr\0cnfg";

			pm8916@0 {
				#address-cells = <0x01>;
				#size-cells = <0x00>;
				compatible = "qcom,pm8916\0qcom,spmi-pmic";
				phandle = <0x8f>;
				reg = <0x00 0x00>;

				gpios@c000 {
					#gpio-cells = <0x02>;
					compatible = "qcom,pm8916-gpio";
					gpio-controller;
					interrupts = <0x00 0xc0 0x00 0x00 0x00 0xc1 0x00 0x00 0x00 0xc2 0x00 0x00 0x00 0xc3 0x00 0x00>;
					phandle = <0x90>;
					reg = <0xc000>;
				};

				mpps@a000 {
					#gpio-cells = <0x02>;
					compatible = "qcom,pm8916-mpp";
					gpio-controller;
					interrupts = <0x00 0xa0 0x00 0x00 0x00 0xa1 0x00 0x00 0x00 0xa2 0x00 0x00 0x00 0xa3 0x00 0x00>;
					phandle = <0x91>;
					reg = <0xa000>;
				};

				pwrkey@800 {
					bias-pull-up;
					compatible = "qcom,pm8941-pwrkey";
					debounce = <0x3d09>;
					interrupts = <0x00 0x08 0x00 0x03>;
					reg = <0x800>;
				};

				rtc@6000 {
					compatible = "qcom,pm8941-rtc";
					interrupts = <0x00 0x61 0x01 0x01>;
					reg = <0x6000>;
					reg-names = "rtc\0alarm";
				};

				temp-alarm@2400 {
					#thermal-sensor-cells = <0x00>;
					compatible = "qcom,spmi-temp-alarm";
					interrupts = <0x00 0x24 0x00 0x01>;
					io-channel-names = "thermal";
					io-channels = <0x22 0x08>;
					phandle = <0x92>;
					reg = <0x2400>;
				};

				vadc@3100 {
					#address-cells = <0x01>;
					#io-channel-cells = <0x01>;
					#size-cells = <0x00>;
					compatible = "qcom,spmi-vadc";
					interrupts = <0x00 0x31 0x00 0x01>;
					phandle = <0x22>;
					reg = <0x3100>;

					die_temp {
						reg = <0x08>;
					};

					ref_1250v {
						reg = <0x0a>;
					};

					ref_625mv {
						reg = <0x09>;
					};

					ref_gnd {
						reg = <0x0e>;
					};

					ref_vdd {
						reg = <0x0f>;
					};

					usb_in {
						qcom,pre-scaling = <0x01 0x0a>;
						reg = <0x00>;
					};

					vph_pwr {
						qcom,pre-scaling = <0x01 0x03>;
						reg = <0x07>;
					};
				};
			};

			pm8916@1 {
				#address-cells = <0x01>;
				#size-cells = <0x00>;
				compatible = "qcom,pm8916\0qcom,spmi-pmic";
				phandle = <0x93>;
				reg = <0x01 0x00>;

				codec@f000 {
					#sound-dai-cells = <0x01>;
					clock-names = "mclk";
					clocks = <0x08 0x9f>;
					compatible = "qcom,pm8916-wcd-analog-codec";
					interrupt-names = "cdc_spk_cnp_int\0cdc_spk_clip_int\0cdc_spk_ocp_int\0mbhc_ins_rem_det1\0mbhc_but_rel_det\0mbhc_but_press_det\0mbhc_ins_rem_det\0mbhc_switch_int\0cdc_ear_ocp_int\0cdc_hphr_ocp_int\0cdc_hphl_ocp_det\0cdc_ear_cnp_int\0cdc_hphr_cnp_int\0cdc_hphl_cnp_int";
					interrupt-parent = <0x23>;
					interrupts = <0x01 0xf0 0x00 0x00 0x01 0xf0 0x01 0x00 0x01 0xf0 0x02 0x00 0x01 0xf0 0x03 0x00 0x01 0xf0 0x04 0x00 0x01 0xf0 0x05 0x00 0x01 0xf0 0x06 0x00 0x01 0xf0 0x07 0x00 0x01 0xf1 0x00 0x00 0x01 0xf1 0x01 0x00 0x01 0xf1 0x02 0x00 0x01 0xf1 0x03 0x00 0x01 0xf1 0x04 0x00 0x01 0xf1 0x05 0x00>;
					phandle = <0x94>;
					reg = <0xf000 0x200>;
					reg-names = "pmic-codec-core";
					vdd-cdc-io-supply = <0x24>;
					vdd-cdc-tx-rx-cx-supply = <0x24>;
					vdd-micbias-supply = <0x25>;
				};
			};
		};

		syscon@1905000 {
			compatible = "syscon";
			phandle = <0x09>;
			reg = <0x1905000 0x20000>;
		};

		syscon@1937000 {
			compatible = "qcom,tcsr-msm8916\0syscon";
			phandle = <0x35>;
			reg = <0x1937000 0x30000>;
		};

		syscon@b011000 {
			compatible = "syscon";
			phandle = <0x38>;
			reg = <0xb011000 0x1000>;
		};

		thermal-sensor@4a8000 {
			#thermal-sensor-cells = <0x01>;
			compatible = "qcom,msm8916-tsens";
			nvmem-cell-names = "calib\0calib_sel";
			nvmem-cells = <0x26 0x27>;
			phandle = <0x04>;
			reg = <0x4a8000 0x2000>;
		};

		timer@b020000 {
			#address-cells = <0x01>;
			#size-cells = <0x01>;
			clock-frequency = <0x124f800>;
			compatible = "arm,armv7-timer-mem";
			ranges;
			reg = <0xb020000 0x1000>;

			frame@b021000 {
				frame-number = <0x00>;
				interrupts = <0x00 0x08 0x04 0x00 0x07 0x04>;
				reg = <0xb021000 0x1000 0xb022000 0x1000>;
			};

			frame@b023000 {
				frame-number = <0x01>;
				interrupts = <0x00 0x09 0x04>;
				reg = <0xb023000 0x1000>;
				status = "disabled";
			};

			frame@b024000 {
				frame-number = <0x02>;
				interrupts = <0x00 0x0a 0x04>;
				reg = <0xb024000 0x1000>;
				status = "disabled";
			};

			frame@b025000 {
				frame-number = <0x03>;
				interrupts = <0x00 0x0b 0x04>;
				reg = <0xb025000 0x1000>;
				status = "disabled";
			};

			frame@b026000 {
				frame-number = <0x04>;
				interrupts = <0x00 0x0c 0x04>;
				reg = <0xb026000 0x1000>;
				status = "disabled";
			};

			frame@b027000 {
				frame-number = <0x05>;
				interrupts = <0x00 0x0d 0x04>;
				reg = <0xb027000 0x1000>;
				status = "disabled";
			};

			frame@b028000 {
				frame-number = <0x06>;
				interrupts = <0x00 0x0e 0x04>;
				reg = <0xb028000 0x1000>;
				status = "disabled";
			};
		};

		tpiu@820000 {
			clock-names = "apb_pclk\0atclk";
			clocks = <0x3d 0x08 0x3d 0x09>;
			compatible = "arm,coresight-tpiu\0arm,primecell";
			reg = <0x820000 0x1000>;

			port {

				endpoint {
					phandle = <0x46>;
					remote-endpoint = <0x42>;
					slave-mode;
				};
			};
		};

		usb@78d9000 {
			#reset-cells = <0x01>;
			ahb-burst-config = <0x00>;
			assigned-clock-rates = <0x4c4b400>;
			assigned-clocks = <0x08 0x86>;
			clock-names = "iface\0core";
			clocks = <0x08 0x85 0x08 0x86>;
			compatible = "qcom,ci-hdrc";
			dr_mode = "otg";
			interrupts = <0x00 0x86 0x04 0x00 0x8c 0x04>;
			phandle = <0x21>;
			phy-names = "usb-phy";
			phy_type = "ulpi";
			phys = <0x20>;
			reg = <0x78d9000 0x200 0x78d9200 0x200>;
			reset-names = "core";
			resets = <0x08 0x22>;
			status = "disabled";

			ulpi {

				phy {
					#phy-cells = <0x00>;
					clock-names = "ref\0sleep";
					clocks = <0x1f 0x08 0x84>;
					compatible = "qcom,usb-hs-phy-msm8916\0qcom,usb-hs-phy";
					phandle = <0x20>;
					qcom,init-seq = <0x44016b 0x2240313>;
					reset-names = "phy\0por";
					resets = <0x08 0x23 0x21 0x00>;
				};
			};
		};

		video-codec@1d00000 {
			clock-names = "core\0iface\0bus";
			clocks = <0x08 0x89 0x08 0x87 0x08 0x88>;
			compatible = "qcom,msm8916-venus";
			interrupts = <0x00 0x2c 0x04>;
			iommus = <0x2b 0x05>;
			memory-region = <0x58>;
			phandle = <0x99>;
			power-domains = <0x08 0x01>;
			reg = <0x1d00000 0xff000>;
			status = "okay";

			video-decoder {
				compatible = "venus-decoder";
			};

			video-encoder {
				compatible = "venus-encoder";
			};
		};

		wcnss@a21b000 {
			compatible = "qcom,pronto-v2-pil\0qcom,pronto";
			interrupt-names = "wdog\0fatal\0ready\0handover\0stop-ack";
			interrupts-extended = <0x01 0x00 0x95 0x01 0x3a 0x00 0x01 0x3a 0x01 0x01 0x3a 0x02 0x01 0x3a 0x03 0x01>;
			memory-region = <0x39>;
			phandle = <0x40>;
			pinctrl-0 = <0x3c>;
			pinctrl-names = "default";
			qcom,state = <0x3b 0x00>;
			qcom,state-names = "stop";
			reg = <0xa204000 0x2000 0xa202000 0x1000 0xa21b000 0x3000>;
			reg-names = "ccu\0dxe\0pmu";
			status = "disabled";
			vddmx-supply = <0x33>;
			vddpx-supply = <0x34>;

			iris {
				clock-names = "xo";
				clocks = <0x3d 0x1c>;
				compatible = "qcom,wcn3620";
				vdddig-supply = <0x24>;
				vddpa-supply = <0x3f>;
				vddrfa-supply = <0x3e>;
				vddxo-supply = <0x34>;
			};

			smd-edge {
				interrupts = <0x00 0x8e 0x01>;
				label = "pronto";
				qcom,ipc = <0x38 0x08 0x11>;
				qcom,remote-pid = <0x04>;
				qcom,smd-edge = <0x06>;

				wcnss {
					compatible = "qcom,wcnss";
					qcom,mmio = <0x40>;
					qcom,smd-channels = "WCNSS_CTRL";

					bt {
						compatible = "qcom,wcnss-bt";
					};

					wifi {
						compatible = "qcom,wcnss-wlan";
						interrupt-names = "tx\0rx";
						interrupts = <0x00 0x91 0x04 0x00 0x92 0x04>;
						qcom,smem-state-names = "tx-enable\0tx-rings-empty";
						qcom,smem-states = <0x41 0x0a 0x41 0x09>;
					};
				};
			};
		};
	};

	thermal-zones {

		cpu-thermal0 {
			polling-delay = <0x3e8>;
			polling-delay-passive = <0xfa>;
			thermal-sensors = <0x04 0x04>;

			trips {

				trip0 {
					hysteresis = <0x7d0>;
					phandle = <0x59>;
					temperature = <0x124f8>;
					type = "passive";
				};

				trip1 {
					hysteresis = <0x7d0>;
					phandle = <0x5a>;
					temperature = <0x1adb0>;
					type = "critical";
				};
			};
		};

		cpu-thermal1 {
			polling-delay = <0x3e8>;
			polling-delay-passive = <0xfa>;
			thermal-sensors = <0x04 0x03>;

			trips {

				trip0 {
					hysteresis = <0x7d0>;
					phandle = <0x5b>;
					temperature = <0x124f8>;
					type = "passive";
				};

				trip1 {
					hysteresis = <0x7d0>;
					phandle = <0x5c>;
					temperature = <0x1adb0>;
					type = "critical";
				};
			};
		};
	};

	timer {
		compatible = "arm,armv8-timer";
		interrupts = <0x01 0x02 0xf08 0x01 0x03 0xf08 0x01 0x04 0xf08 0x01 0x01 0xf08>;
	};

	wcnss-smp2p {
		compatible = "qcom,smp2p";
		interrupts = <0x00 0x8f 0x01>;
		qcom,ipc = <0x38 0x08 0x12>;
		qcom,local-pid = <0x00>;
		qcom,remote-pid = <0x04>;
		qcom,smem = <0x1c3 0x1af>;

		master-kernel {
			#qcom,smem-state-cells = <0x01>;
			phandle = <0x3b>;
			qcom,entry-name = "master-kernel";
		};

		slave-kernel {
			#interrupt-cells = <0x02>;
			interrupt-controller;
			phandle = <0x3a>;
			qcom,entry-name = "slave-kernel";
		};
	};
};
